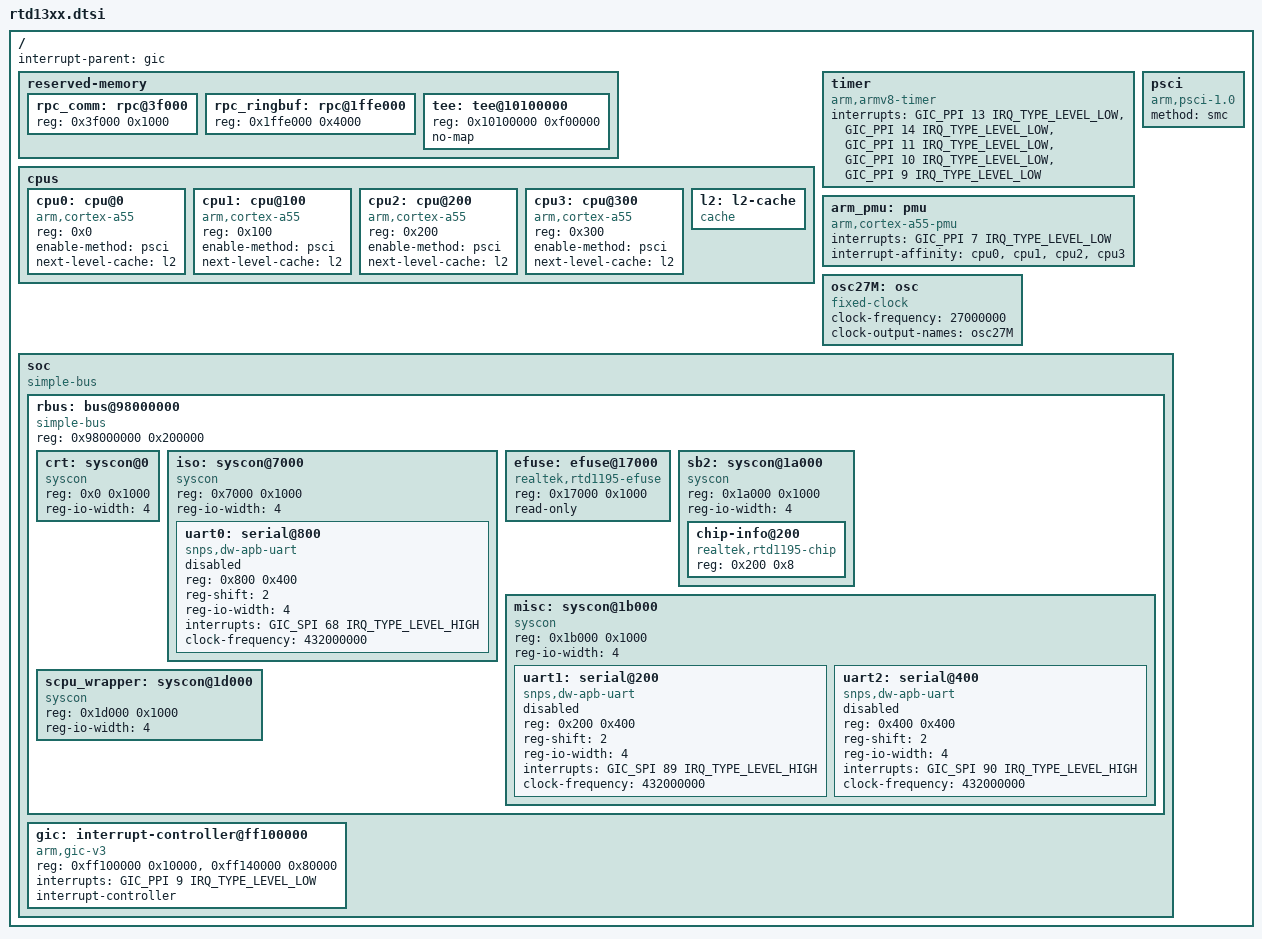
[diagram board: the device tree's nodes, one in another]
// SPDX-License-Identifier: (GPL-2.0-or-later OR BSD-2-Clause)
/*
 * Realtek RTD13xx SoC family
 *
 * Copyright (c) 2019-2020 Realtek Semiconductor Corp.
 */

/memreserve/	0x0000000000000000 0x000000000002e000; /* Boot ROM */
/memreserve/	0x000000000002e000 0x0000000000100000; /* Boot loader */
/memreserve/	0x000000000f400000 0x0000000000500000; /* Video FW */
/memreserve/	0x000000000f900000 0x0000000000500000; /* Audio FW */
/memreserve/	0x0000000010000000 0x0000000000014000; /* Audio FW RAM */

#include <dt-bindings/interrupt-controller/arm-gic.h>
#include <dt-bindings/interrupt-controller/irq.h>

/ {
	interrupt-parent = <&gic>;
	#address-cells = <1>;
	#size-cells = <1>;

	reserved-memory {
		#address-cells = <1>;
		#size-cells = <1>;
		ranges;

		rpc_comm: rpc@3f000 {
			reg = <0x3f000 0x1000>;
		};

		rpc_ringbuf: rpc@1ffe000 {
			reg = <0x1ffe000 0x4000>;
		};

		tee: tee@10100000 {
			reg = <0x10100000 0xf00000>;
			no-map;
		};
	};

	cpus {
		#address-cells = <1>;
		#size-cells = <0>;

		cpu0: cpu@0 {
			device_type = "cpu";
			compatible = "arm,cortex-a55";
			reg = <0x0>;
			enable-method = "psci";
			next-level-cache = <&l2>;
		};

		cpu1: cpu@100 {
			device_type = "cpu";
			compatible = "arm,cortex-a55";
			reg = <0x100>;
			enable-method = "psci";
			next-level-cache = <&l2>;
		};

		cpu2: cpu@200 {
			device_type = "cpu";
			compatible = "arm,cortex-a55";
			reg = <0x200>;
			enable-method = "psci";
			next-level-cache = <&l2>;
		};

		cpu3: cpu@300 {
			device_type = "cpu";
			compatible = "arm,cortex-a55";
			reg = <0x300>;
			enable-method = "psci";
			next-level-cache = <&l2>;
		};

		l2: l2-cache {
			compatible = "cache";
		};
	};

	timer {
		compatible = "arm,armv8-timer";
		interrupts = <GIC_PPI 13 IRQ_TYPE_LEVEL_LOW>,
			     <GIC_PPI 14 IRQ_TYPE_LEVEL_LOW>,
			     <GIC_PPI 11 IRQ_TYPE_LEVEL_LOW>,
			     <GIC_PPI 10 IRQ_TYPE_LEVEL_LOW>,
			     <GIC_PPI 9 IRQ_TYPE_LEVEL_LOW>;
	};

	arm_pmu: pmu {
		compatible = "arm,cortex-a55-pmu";
		interrupts = <GIC_PPI 7 IRQ_TYPE_LEVEL_LOW>;
		interrupt-affinity = <&cpu0>, <&cpu1>, <&cpu2>, <&cpu3>;
	};

	psci {
		compatible = "arm,psci-1.0";
		method = "smc";
	};

	osc27M: osc {
		compatible = "fixed-clock";
		clock-frequency = <27000000>;
		clock-output-names = "osc27M";
		#clock-cells = <0>;
	};

	soc {
		compatible = "simple-bus";
		#address-cells = <1>;
		#size-cells = <1>;
		ranges = <0x00000000 0x00000000 0x0002e000>, /* boot ROM */
			 <0xff100000 0xff100000 0x00200000>, /* GIC */
			 <0x98000000 0x98000000 0x00200000>; /* rbus */

		rbus: bus@98000000 {
			compatible = "simple-bus";
			reg = <0x98000000 0x200000>;
			#address-cells = <1>;
			#size-cells = <1>;
			ranges = <0x0 0x98000000 0x200000>;

			crt: syscon@0 {
				compatible = "syscon", "simple-mfd";
				reg = <0x0 0x1000>;
				reg-io-width = <4>;
				#address-cells = <1>;
				#size-cells = <1>;
				ranges = <0x0 0x0 0x1000>;
			};

			iso: syscon@7000 {
				compatible = "syscon", "simple-mfd";
				reg = <0x7000 0x1000>;
				reg-io-width = <4>;
				#address-cells = <1>;
				#size-cells = <1>;
				ranges = <0x0 0x7000 0x1000>;
			};

			efuse: efuse@17000 {
				compatible = "realtek,rtd1195-efuse";
				reg = <0x17000 0x1000>;
				read-only;
				#address-cells = <1>;
				#size-cells = <1>;
			};

			sb2: syscon@1a000 {
				compatible = "syscon", "simple-mfd";
				reg = <0x1a000 0x1000>;
				reg-io-width = <4>;
				#address-cells = <1>;
				#size-cells = <1>;
				ranges = <0x0 0x1a000 0x1000>;
			};

			misc: syscon@1b000 {
				compatible = "syscon", "simple-mfd";
				reg = <0x1b000 0x1000>;
				reg-io-width = <4>;
				#address-cells = <1>;
				#size-cells = <1>;
				ranges = <0x0 0x1b000 0x1000>;
			};

			scpu_wrapper: syscon@1d000 {
				compatible = "syscon", "simple-mfd";
				reg = <0x1d000 0x1000>;
				reg-io-width = <4>;
				#address-cells = <1>;
				#size-cells = <1>;
				ranges = <0x0 0x1d000 0x1000>;
			};
		};

		gic: interrupt-controller@ff100000 {
			compatible = "arm,gic-v3";
			reg = <0xff100000 0x10000>,
			      <0xff140000 0x80000>;
			interrupts = <GIC_PPI 9 IRQ_TYPE_LEVEL_LOW>;
			interrupt-controller;
			#interrupt-cells = <3>;
		};
	};
};

&iso {
	uart0: serial@800 {
		compatible = "snps,dw-apb-uart";
		reg = <0x800 0x400>;
		reg-shift = <2>;
		reg-io-width = <4>;
		interrupts = <GIC_SPI 68 IRQ_TYPE_LEVEL_HIGH>;
		clock-frequency = <432000000>;
		status = "disabled";
	};
};

&misc {
	uart1: serial@200 {
		compatible = "snps,dw-apb-uart";
		reg = <0x200 0x400>;
		reg-shift = <2>;
		reg-io-width = <4>;
		interrupts = <GIC_SPI 89 IRQ_TYPE_LEVEL_HIGH>;
		clock-frequency = <432000000>;
		status = "disabled";
	};

	uart2: serial@400 {
		compatible = "snps,dw-apb-uart";
		reg = <0x400 0x400>;
		reg-shift = <2>;
		reg-io-width = <4>;
		interrupts = <GIC_SPI 90 IRQ_TYPE_LEVEL_HIGH>;
		clock-frequency = <432000000>;
		status = "disabled";
	};
};

&sb2 {
	chip-info@200 {
		compatible = "realtek,rtd1195-chip";
		reg = <0x200 0x8>;
	};
};
